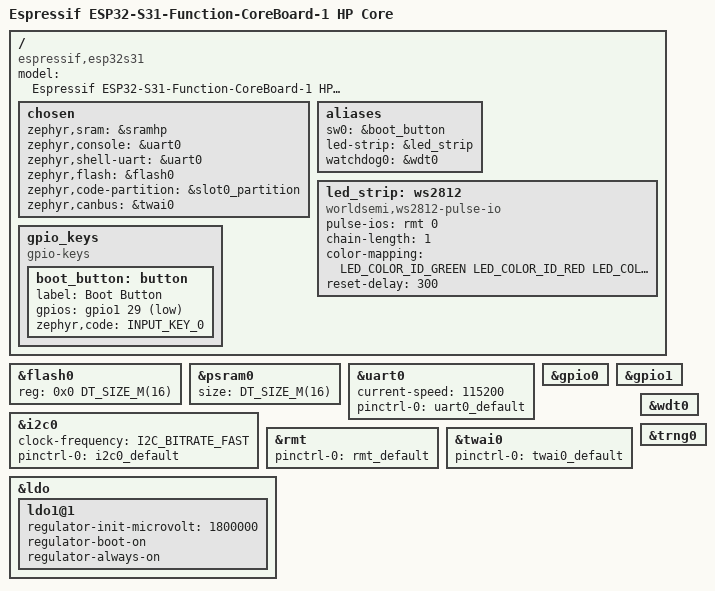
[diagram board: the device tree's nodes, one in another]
/*
 * Copyright (c) 2026 Espressif Systems (Shanghai) Co., Ltd.
 *
 * SPDX-License-Identifier: Apache-2.0
 */

/dts-v1/;

#include <espressif/esp32s31/esp32s31.dtsi>
#include "esp32s31_function_coreboard_hpcore-pinctrl.dtsi"
#include <zephyr/dt-bindings/input/input-event-codes.h>
#include <zephyr/dt-bindings/led/led.h>
#include <espressif/partitions_0x2000_default_16M.dtsi>

/ {
	compatible = "espressif,esp32s31";
	model = "Espressif ESP32-S31-Function-CoreBoard-1 HP Core";

	chosen {
		zephyr,sram = &sramhp;
		zephyr,console = &uart0;
		zephyr,shell-uart = &uart0;
		zephyr,flash = &flash0;
		zephyr,code-partition = &slot0_partition;
		zephyr,canbus = &twai0;
	};

	aliases {
		sw0 = &boot_button;
		led-strip = &led_strip;
		watchdog0 = &wdt0;
	};

	led_strip: ws2812 {
		compatible = "worldsemi,ws2812-pulse-io";
		pulse-ios = <&rmt 0>;
		chain-length = <1>;
		color-mapping = <LED_COLOR_ID_GREEN
				 LED_COLOR_ID_RED
				 LED_COLOR_ID_BLUE>;
		reset-delay = <300>;
	};

	gpio_keys {
		compatible = "gpio-keys";

		boot_button: button {
			label = "Boot Button";
			gpios = <&gpio1 29 (GPIO_PULL_UP | GPIO_ACTIVE_LOW)>;
			zephyr,code = <INPUT_KEY_0>;
		};
	};
};

&flash0 {
	reg = <0x0 DT_SIZE_M(16)>;
	ranges = <0x0 0x0 DT_SIZE_M(16)>;
};

&psram0 {
	size = <DT_SIZE_M(16)>;
};

&uart0 {
	current-speed = <115200>;
	pinctrl-0 = <&uart0_default>;
	pinctrl-names = "default";
	status = "okay";
};

&i2c0 {
	clock-frequency = <I2C_BITRATE_FAST>;
	pinctrl-0 = <&i2c0_default>;
	pinctrl-names = "default";
	status = "okay";
};

&gpio0 {
	status = "okay";
};

&gpio1 {
	status = "okay";
};

&rmt {
	pinctrl-0 = <&rmt_default>;
	pinctrl-names = "default";
	status = "okay";
};

&twai0 {
	pinctrl-0 = <&twai0_default>;
	pinctrl-names = "default";
	status = "okay";
};

&wdt0 {
	status = "okay";
};

&trng0 {
	status = "okay";
};

/* Internal LDO channel 1 powers the on-board PSRAM at 1.8 V. */
&ldo {
	status = "okay";

	ldo1@1 {
		regulator-init-microvolt = <1800000>;
		regulator-boot-on;
		regulator-always-on;
	};
};
